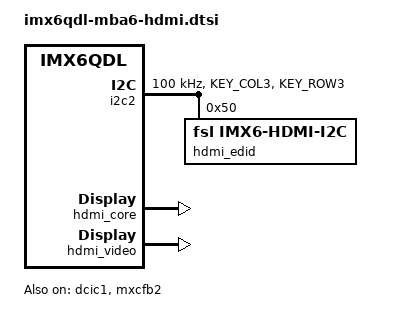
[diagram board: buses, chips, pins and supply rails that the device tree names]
// SPDX-License-Identifier: GPL-2.0-only
/*
 * Copyright 2015-2017-2022 TQ-Systems GmbH
 * Author: Markus Niebel <linux@ew.tq-group.com>
 */

&dcic1 {
	dcic_id = <0>;
	dcic_mux = "dcic-hdmi";
	status = "okay";
};

&i2c2 {
	clock-frequency = <100000>;
	pinctrl-names = "default";
	pinctrl-0 = <&pinctrl_i2c2>;
	status = "okay";

	hdmi_edid: edid@50 {
		compatible = "fsl,imx6-hdmi-i2c";
		reg = <0x50>;
	};
};

&hdmi_cec {
	pinctrl-names = "default";
	pinctrl-0 = <&pinctrl_hdmi_cec>;
	status = "disabled";
};

&hdmi_core {
	ipu_id = <0>;
	disp_id = <0>;
	status = "okay";
};

&hdmi_video {
	fsl,phy_reg_vlev = <0x0294>;
	fsl,phy_reg_cksymtx = <0x800d>;
	status = "okay";
};

&iomuxc {
	pinctrl_hdmi_cec: hdmicecgrp {
		fsl,pins = <
			MX6QDL_PAD_KEY_ROW2__HDMI_TX_CEC_LINE 0x1f8b0
		>;
	};

	pinctrl_i2c2: i2c2grp {
		fsl,pins = <
			MX6QDL_PAD_KEY_COL3__I2C2_SCL 0x4001b899
			MX6QDL_PAD_KEY_ROW3__I2C2_SDA 0x4001b899
		>;
	};
};

&mxcfb2 {
	disp_dev = "hdmi";
	interface_pix_fmt = "RGB24";
	mode_str ="1920x1080M@60";
	default_bpp = <32>;
	int_clk = <0>;
	late_init = <0>;
	status = "okay";
};
